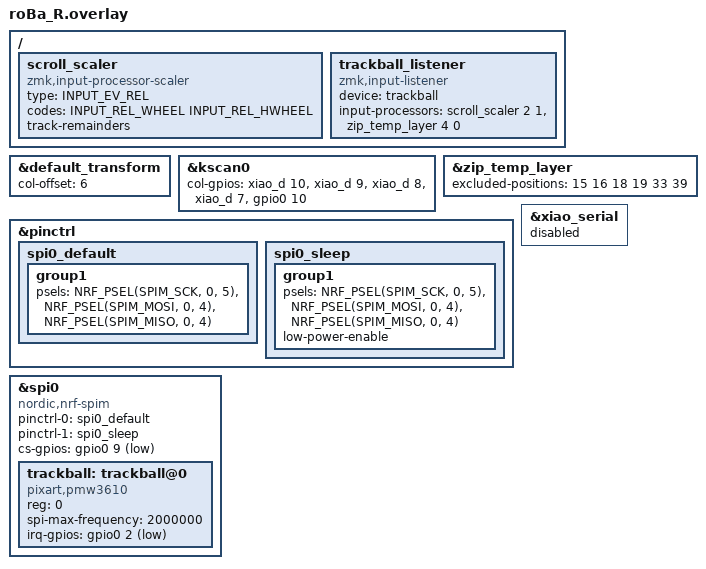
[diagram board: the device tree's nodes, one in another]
#include "roBa.dtsi"
#include <input/processors.dtsi>

&default_transform {
    col-offset = <6>;
};

&kscan0 {
        col-gpios
            = <&xiao_d 10 GPIO_ACTIVE_HIGH>
            , <&xiao_d 9 GPIO_ACTIVE_HIGH>
            , <&xiao_d 8 GPIO_ACTIVE_HIGH>
            , <&xiao_d 7 GPIO_ACTIVE_HIGH>
            , <&gpio0 10 GPIO_ACTIVE_HIGH>
            ;
};

/ {
    // マウススクロール量を調整するためのスケーラー
    // <倍率 除数> = <2 1> でスクロール量を2倍に。倍率を上げるほど多くなる
    scroll_scaler: scroll_scaler {
        compatible = "zmk,input-processor-scaler";
        #input-processor-cells = <2>;
        type = <INPUT_EV_REL>;
        codes = <INPUT_REL_WHEEL INPUT_REL_HWHEEL>;
        track-remainders;
    };

    trackball_listener {
        status = "okay";
        compatible = "zmk,input-listener";
        device = <&trackball>;
        // トラックボール操作でMOUSEレイヤー(4)を有効化する。
        // timeout=0のため時間経過では解除せず、キー押下でのみ解除する。
        input-processors = <&scroll_scaler 2 1 &zip_temp_layer 4 0>;
    };
};

&zip_temp_layer {
    // Ctrl/Command/ShiftのホールドとJ/Kのクリック中はMOUSEレイヤーを維持する。
    // 修飾キー兼用キーのタップ側は専用behaviorから明示的に解除する。
    excluded-positions = <15 16 18 19 33 39>;
};

&pinctrl {
    spi0_default: spi0_default {
        group1 {
            psels = <NRF_PSEL(SPIM_SCK, 0, 5)>,
                <NRF_PSEL(SPIM_MOSI, 0, 4)>,
                <NRF_PSEL(SPIM_MISO, 0, 4)>;
        };
    };

    spi0_sleep: spi0_sleep {
        group1 {
            psels = <NRF_PSEL(SPIM_SCK, 0, 5)>,
                <NRF_PSEL(SPIM_MOSI, 0, 4)>,
                <NRF_PSEL(SPIM_MISO, 0, 4)>;
            low-power-enable;
        };
    };
};

&xiao_serial { status = "disabled"; };

&spi0 {
    status = "okay";
    compatible = "nordic,nrf-spim";
    pinctrl-0 = <&spi0_default>;
    pinctrl-1 = <&spi0_sleep>;
    pinctrl-names = "default", "sleep";
    cs-gpios = <&gpio0 9 GPIO_ACTIVE_LOW>;

    trackball: trackball@0 {
        status = "okay";
        compatible = "pixart,pmw3610";
        reg = <0>;
        spi-max-frequency = <2000000>;
        irq-gpios = <&gpio0 2 (GPIO_ACTIVE_LOW | GPIO_PULL_UP)>;
    };
};
